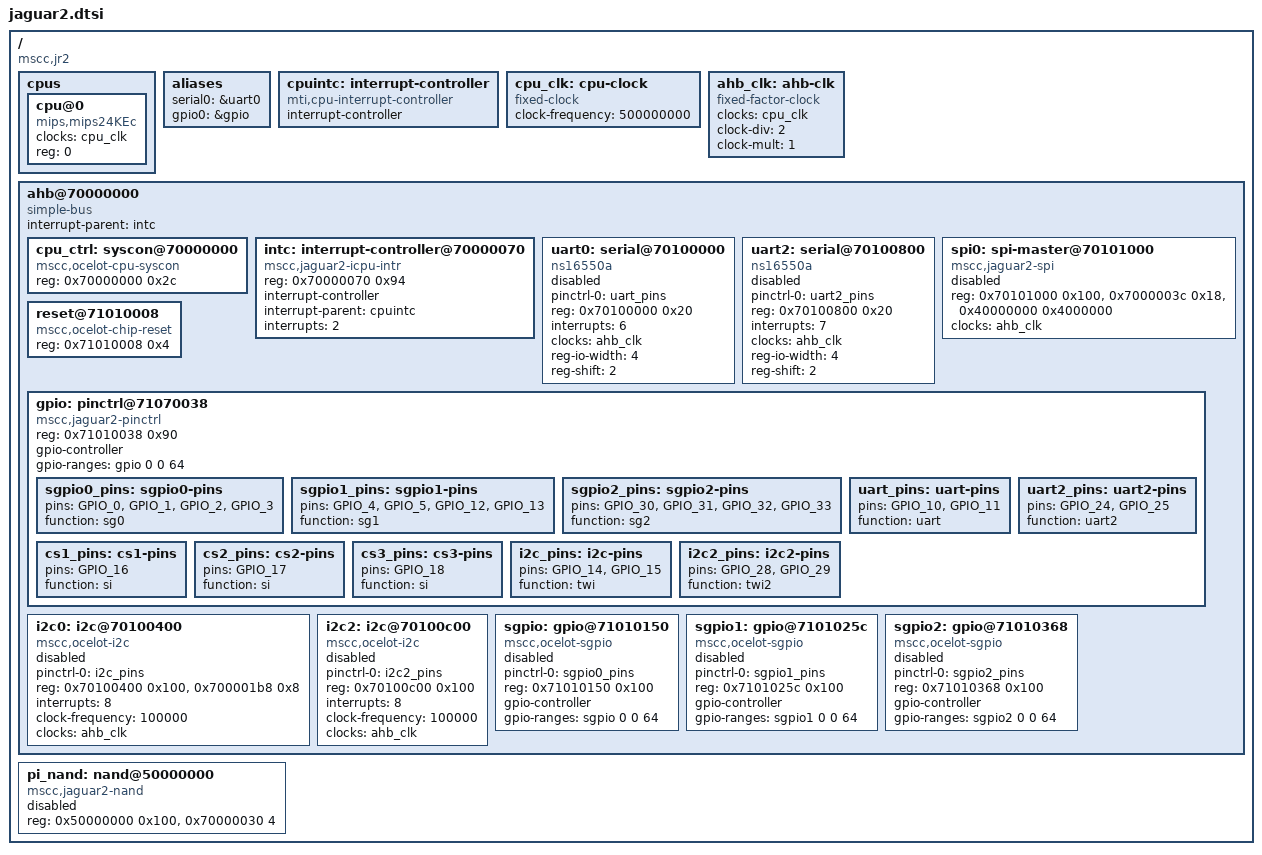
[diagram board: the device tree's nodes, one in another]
// SPDX-License-Identifier: (GPL-2.0+ OR MIT)
/*
 * Copyright (c) 2018 Microsemi Corporation
 */

/ {
	#address-cells = <1>;
	#size-cells = <1>;
	compatible = "mscc,jr2";

	cpus {
		#address-cells = <1>;
		#size-cells = <0>;

		cpu@0 {
			compatible = "mips,mips24KEc";
			device_type = "cpu";
			clocks = <&cpu_clk>;
			reg = <0>;
		};
	};

	aliases {
		serial0 = &uart0;
		gpio0 = &gpio;
	};

	cpuintc: interrupt-controller {
		#address-cells = <0>;
		#interrupt-cells = <1>;
		interrupt-controller;
		compatible = "mti,cpu-interrupt-controller";
	};

	cpu_clk: cpu-clock {
		compatible = "fixed-clock";
		#clock-cells = <0>;
		clock-frequency = <500000000>;
	};

	ahb_clk: ahb-clk {
		compatible = "fixed-factor-clock";
		#clock-cells = <0>;
		clocks = <&cpu_clk>;
		clock-div = <2>;
		clock-mult = <1>;
	};

	ahb@70000000 {
		compatible = "simple-bus";
		#address-cells = <1>;
		#size-cells = <1>;
		ranges;

		interrupt-parent = <&intc>;

		cpu_ctrl: syscon@70000000 {
			compatible = "mscc,ocelot-cpu-syscon", "syscon";
			reg = <0x70000000 0x2c>;
		};

		intc: interrupt-controller@70000070 {
			compatible = "mscc,jaguar2-icpu-intr";
			reg = <0x70000070 0x94>;
			#interrupt-cells = <1>;
			interrupt-controller;
			interrupt-parent = <&cpuintc>;
			interrupts = <2>;
		};

		uart0: serial@70100000 {
			pinctrl-0 = <&uart_pins>;
			pinctrl-names = "default";
			compatible = "ns16550a";
			reg = <0x70100000 0x20>;
			interrupts = <6>;
			clocks = <&ahb_clk>;
			reg-io-width = <4>;
			reg-shift = <2>;

			status = "disabled";
		};

		uart2: serial@70100800 {
			pinctrl-0 = <&uart2_pins>;
			pinctrl-names = "default";
			compatible = "ns16550a";
			reg = <0x70100800 0x20>;
			interrupts = <7>;
			clocks = <&ahb_clk>;
			reg-io-width = <4>;
			reg-shift = <2>;

			status = "disabled";
		};

		spi0: spi-master@70101000 {
			compatible = "mscc,jaguar2-spi", "snps,dw-apb-ssi";
			#address-cells = <1>;
			#size-cells = <0>;
			reg = <0x70101000 0x100>, <0x7000003c 0x18>, <0x40000000 0x4000000>;
			clocks = <&ahb_clk>;

			status = "disabled";
		};

		reset@71010008 {
			compatible = "mscc,ocelot-chip-reset";
			reg = <0x71010008 0x4>;
		};

		gpio: pinctrl@71070038 {
			compatible = "mscc,jaguar2-pinctrl";
			reg = <0x71010038 0x90>;
			gpio-controller;
			#gpio-cells = <2>;
			gpio-ranges = <&gpio 0 0 64>;

			sgpio0_pins: sgpio0-pins {
				pins = "GPIO_0", "GPIO_1", "GPIO_2", "GPIO_3";
				function = "sg0";
			};

			sgpio1_pins: sgpio1-pins {
				pins = "GPIO_4", "GPIO_5", "GPIO_12", "GPIO_13";
				function = "sg1";
			};

			sgpio2_pins: sgpio2-pins {
				pins = "GPIO_30", "GPIO_31", "GPIO_32", "GPIO_33";
				function = "sg2";
			};

			uart_pins: uart-pins {
				pins = "GPIO_10", "GPIO_11";
				function = "uart";
			};

			uart2_pins: uart2-pins {
				pins = "GPIO_24", "GPIO_25";
				function = "uart2";
			};

			cs1_pins: cs1-pins {
				pins = "GPIO_16";
				function = "si";
			};

			cs2_pins: cs2-pins {
				pins = "GPIO_17";
				function = "si";
			};

			cs3_pins: cs3-pins {
				pins = "GPIO_18";
				function = "si";
			};

			i2c_pins: i2c-pins {
				pins = "GPIO_14", "GPIO_15";
				function = "twi";
			};

			i2c2_pins: i2c2-pins {
				pins = "GPIO_28", "GPIO_29";
				function = "twi2";
			};
		};

		i2c0: i2c@70100400 {
			compatible = "mscc,ocelot-i2c", "snps,designware-i2c";
			status = "disabled";
			pinctrl-0 = <&i2c_pins>;
			pinctrl-names = "default";
			reg = <0x70100400 0x100>, <0x700001b8 0x8>;
			#address-cells = <1>;
			#size-cells = <0>;
			interrupts = <8>;
			clock-frequency = <100000>;
			clocks = <&ahb_clk>;
		};

		i2c2: i2c@70100c00 {
			compatible = "mscc,ocelot-i2c", "snps,designware-i2c";
			status = "disabled";
			pinctrl-0 = <&i2c2_pins>;
			pinctrl-names = "default";
			reg = <0x70100c00 0x100>;
			#address-cells = <1>;
			#size-cells = <0>;
			interrupts = <8>;
			clock-frequency = <100000>;
			clocks = <&ahb_clk>;
		};

		sgpio: gpio@71010150 {
			compatible = "mscc,ocelot-sgpio";
			status = "disabled";
			pinctrl-0 = <&sgpio0_pins>;
			pinctrl-names = "default";
			reg = <0x71010150 0x100>;
			gpio-controller;
			#gpio-cells = <2>;
			gpio-ranges = <&sgpio 0 0 64>;
		};

		sgpio1: gpio@7101025c {
			compatible = "mscc,ocelot-sgpio";
			status = "disabled";
			pinctrl-0 = <&sgpio1_pins>;
			pinctrl-names = "default";
			reg = <0x7101025c 0x100>;
			gpio-controller;
			#gpio-cells = <2>;
			gpio-ranges = <&sgpio1 0 0 64>;
		};

		sgpio2: gpio@71010368 {
			compatible = "mscc,ocelot-sgpio";
			status = "disabled";
			pinctrl-0 = <&sgpio2_pins>;
			pinctrl-names = "default";
			reg = <0x71010368 0x100>;
			gpio-controller;
			#gpio-cells = <2>;
			gpio-ranges = <&sgpio2 0 0 64>;
		};
	};

	pi_nand: nand@50000000 {
		compatible = "mscc,jaguar2-nand";
		status = "disabled";
		reg = <0x50000000 0x100>, <0x70000030 4>;
	};
};
